# STM32MP21_CA35 register map
File version: 0.4
CPU: CM33 r0p1, little endian, MPU, FPU, vendor SysTick, 8 interrupt priority bits
Registers are 32-bit, read-write, reset 0x0 unless marked. A register's access mark holds for its fields unless they carry their own. Offsets are from the block's base; [hi:lo] are bit positions.

## USBH_EHCI — USBH address block description
Base 0x482F0000
Same registers: USBH_OHCI 0x482E0000, USBH_OHCI_S 0x582E0000, USBH_EHCI_S 0x582F0000
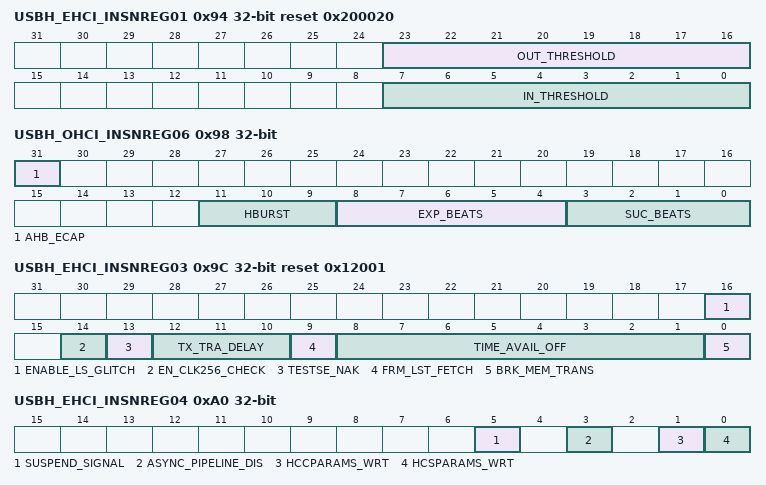
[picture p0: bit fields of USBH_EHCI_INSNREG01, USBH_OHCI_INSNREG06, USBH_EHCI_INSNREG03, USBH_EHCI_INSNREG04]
0x94 USBH_EHCI_INSNREG01 reset 0x200020 — USBH EHCI implementation register #1
  [23:16] OUT_THRESHOLD — The value specified here is the number of 32-bit words The OUT threshold is used to start the USB transfer as soon as the OUT_THRESHOLD amount of data is fetched from system memory. It is also used to disconnect the data fetch, if the required space to hold the threshold amount of data is not available in the packet buffer.
  [7:0] IN_THRESHOLD — The value specified here is the number of 32-bit words The IN threshold is used to start the memory transfer as soon as the IN_THRESHOLD amount of data is available in the packet buffer. It is also used to disconnect the data write, if the threshold amount of data is not available in the packet buffer.
0x98 USBH_OHCI_INSNREG06 — USBH OHCI implementation register #6
  [31] AHB_ECAP — AHB error captured Indicator that an AHB error was encountered and values were captured. To clear this field the application must write a 0 to this register.
  [11:9] HBURST ro — HBURST value of the control phase at which the AHB error occurred
  [8:4] EXP_BEATS ro — Number of expected beats Number of beats expected in the burst where the AHB error occurred. Valid values are 0 and 4. Other values except 4 are not written to EXP_BEATS[4:0].
    0=When no error, 0 is written to EXP_BEATS[4:0]
  [3:0] SUC_BEATS ro — Number of successful beats Number of successfully completed beats in the current burst before the AHB error has occurred.
0x98 USBH_EHCI_INSNREG02 reset 0x80 (alternate view of USBH_OHCI_INSNREG06) — USBH EHCI implementation register #2
  [7:0] PKT_BUF — Programmable packet buffer depth Programmable packet buffer depth. The value specified here represents the number of 32-bit words. Maximum valid packet buffer depth is 128 (32-bit words).
0x9C USBH_OHCI_INSNREG07 ro — USBH OHCI implementation register #7
  [31:0] AHB_MST_ERR — AHB master error address AHB address of the control phase at which the AHB error has occurred. This field is valid only when INSNREG06 [31] is set.
0x9C USBH_EHCI_INSNREG03 reset 0x12001 (alternate view of USBH_OHCI_INSNREG07) — USBH EHCI implementation register #3
  [16] ENABLE_LS_GLITCH — Enable/disable enhancement for line state glitch By default this enhancement is enabled.
    0=disabled; 1=enabled
  [14] EN_CLK256_CHECK — Enable 256 clock checking This bit controls the end of resume sequence of the EHCI host controller. By default, the value of this bit is 0 and during the end of resume sequence, the host controller waits for SE0 on the linestate before switching the PHY to high-speed. When set to 1, during the end of resume sequence, the controller waits for SE0 or 256 clocks before switching the PHY to high-speed. Setting this bit to 1, enables the 256 clock checking. Some of the UTMI PHYs do not present SE0 on the linestate during the end of resume sequence. For such PHYs, this bit should be set, so that the core does not wait forever for SE0. This bit should be set only during initialization.
  [13] TESTSE_NAK — TestSE NAK Ignore linestate during TestSE0 Nak When set to 1 (default), the core ignores the linestate checking when transmitting SOF during the SE0_NAK test mode. When set to 0, the port state machine disables the port if it does not find the linestate to be in SE0 when transmitting SOF during the SE0_NAK testing. While doing impedance measurement during the SE0_NAK testing, the linestate can go to non SE0 forcing the core to disable the port. This bit is used to control the port behavior during this state.
  [12:10] TX_TRA_DELAY — Tx-Tx turnaround delay add on This field specifies the extra delays in phy_clks to be added to the 'Transmit to Transmit turnaround delay' value maintained in the core. The default value of this register field is 0. This default value of 0 is sufficient for most PHYs. But for some PHYs that put wait states during the token packet, it may be required to program a value greater than 0 to meet the transmit to transmit minimum turnaround time. The recommendation is to use the default value of 0 and change it only if there is an issue with minimum transmit-to-transmit turnaround time. This value should be programmed during core initialization and should not be changed afterwards.
  [9] FRM_LST_FETCH — Setting this bit forces the host controller to fetch the periodic frame list in every microframe of a frame. If not set, then the periodic frame list is fetched only in microframe 0 of every frame. The default is 0 (not set). This bit can be changed only during core initialization and should not be changed afterwards.
  [8:1] TIME_AVAIL_OFF — Time available offset This value indicates the additional number of bytes to be accommodated for the time-available calculation. The USB traffic on the bus can be started only when sufficient time is available to complete the packet within the EOF1 point. Refer to the USB 2.0 specification for details of the EOF1 point. This time-available calculation is done in the hardware, and can be further offset by programming a value in this location. Note: Time-available calculation is added for future flexibility. The application is not required to program this field by default.
  [0] BRK_MEM_TRANS ro — Break memory transfer Used in conjunction with EHCI_H_INSNREG01 to enable breaking memory transactions into chunks once the OUT/IN threshold value is reached. Value is fixed to 1.
0xA0 USBH_EHCI_INSNREG04 — USBH EHCI implementation register #4
  [5] SUSPEND_SIGNAL — Suspend signal For systems where the host is halted without waking up all ports out of suspend, the port can become stuck because the clock coming from the PHY is not running when the halt is programmed. To avoid this, the EHCI automatically pulls ports out of suspend when the host is halted by software. This bit is used to disable this automatic function.
    0=By default, the automatic feature is enabled. The suspend signal is de-asserted (logic level 1) when run/stop is reset by software, but the HCH (hchalted) bit is not yet set.; 1=Disables the automatic feature, which takes all ports out of suspend when software clears the run/stop bit. This is for backward compatibility.
  [3] ASYNC_PIPELINE_DIS — Asynchronous pipeline disable The default value is 0 (not set). If set to 1, disables the fetch control state machine to queue further transaction to the asynchronous queue head if the USB transaction is pending for the queue head.
  [1] HCCPARAMS_WRT — When this bit is 1, the USBH_EHCI_HCCPARAMS register bits 17, 15:4, and 2:0 become writable.
  [0] HCSPARAMS_WRT — When this bit is 1, the USBH_EHCI_HCSPARAMS register becomes writable.
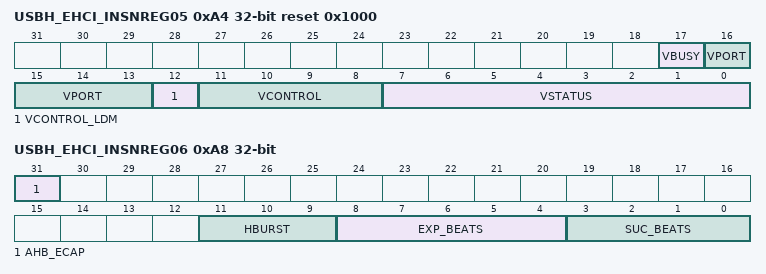
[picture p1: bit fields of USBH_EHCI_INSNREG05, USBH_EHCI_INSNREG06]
0xA4 USBH_EHCI_INSNREG05 reset 0x1000 — USBH EHCI implementation register #5
  [17] VBUSY ro — UTMI VBUSY VBusy (read only). Hardware indicator that a write to this register has occurred and the hardware is currently processing the operation defined by the data written. When processing is finished, this bit is cleared.
  [16:13] VPORT — UTMI VPORT VPort (read write). Valid values for write are only 1 and 2. No other values should be written to this field. Supposing an illegal value, say 4, is written, any subsequent writes to this register are ignored and the read value is always the initial illegal value written (in this case 4).
  [12] VCONTROL_LDM — UTMI VCONTROLLoad (vendor control load) Refer to the UTMI specification for detailed usage.
    0=Load; 1=NOP
  [11:8] VCONTROL — UTMI VCONTROL (vendor control) Vendor defined 4-bit parallel input bus. Refer to the UTMI specification for detailed usage.
  [7:0] VSTATUS ro — UTMI VStatus (vendor status) Refer to the UTMI specification for detailed usage.
0xA8 USBH_EHCI_INSNREG06 — USBH EHCI implementation register #6
  [31] AHB_ECAP — AHB error captured Indicator that an AHB error was encountered and values were captured. To clear this field the application must write a 0 to this bit.
  [11:9] HBURST ro — HBURST value of the control phase at which the AHB error occurred
  [8:4] EXP_BEATS ro — Number of expected beats Number of beats expected in the burst at which the AHB error has occurred. Valid values are 0 to 16. Other values except 4, 8, and 16 are not written to EXP_BEATS[4:0]
    0=When no error, 0 is written to EXP_BEATS[4:0]
  [3:0] SUC_BEATS ro — Number of successful beats Number of successfully-completed beats in the current burst before the AHB error has occurred.
0xAC USBH_EHCI_INSNREG07 ro — USBH EHCI implementation register #7
  [31:0] AHB_MST_ERR — AHB master error address AHB address of the control phase at which the AHB error has occurred.
